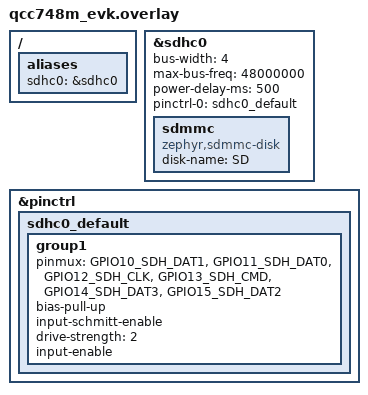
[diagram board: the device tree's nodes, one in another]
/*
 * Copyright (c) 2026 Qualcomm Technologies, Inc. and/or its subsidiaries
 *
 * SPDX-License-Identifier: Apache-2.0
 */

/ {
	aliases {
		sdhc0 = &sdhc0;
	};
};

&sdhc0 {
	status = "okay";
	bus-width = <4>;
	max-bus-freq = <48000000>;
	power-delay-ms = <500>;
	pinctrl-0 = <&sdhc0_default>;
	pinctrl-names = "default";

	sdmmc {
		compatible = "zephyr,sdmmc-disk";
		disk-name = "SD";
		status = "okay";
	};
};

&pinctrl {
	sdhc0_default: sdhc0_default {
		group1 {
			pinmux = <GPIO10_SDH_DAT1>,
				 <GPIO11_SDH_DAT0>,
				 <GPIO12_SDH_CLK>,
				 <GPIO13_SDH_CMD>,
				 <GPIO14_SDH_DAT3>,
				 <GPIO15_SDH_DAT2>;
			bias-pull-up;
			input-schmitt-enable;
			drive-strength = <2>;
			input-enable;
		};
	};
};
